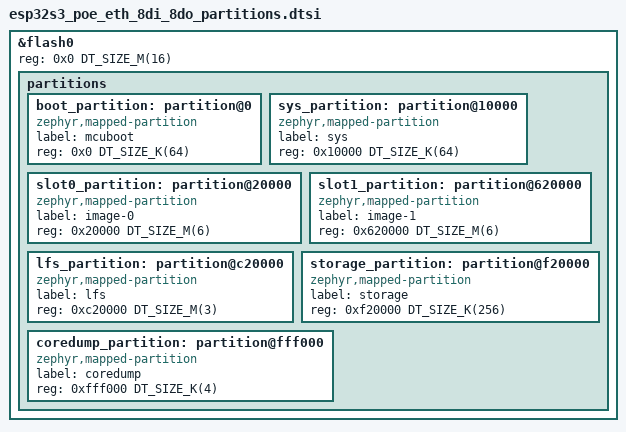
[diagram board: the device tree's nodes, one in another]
/*
 * 16 MB flash layout (ESP32-S3-WROOM-1U-N16R8).
 *
 * Two 6 MB image slots keep room for MCUboot A/B updates (FW-1), a 3 MB
 * LittleFS volume holds the configuration file (CFG-2) and a separate
 * partition backs the settings subsystem (ZMS) for bdSeq (SPB-3).
 *
 * SPDX-License-Identifier: Apache-2.0
 */

&flash0 {
	reg = <0x0 DT_SIZE_M(16)>;
	ranges = <0x0 0x0 DT_SIZE_M(16)>;

	partitions {
		ranges;
		#address-cells = <1>;
		#size-cells = <1>;

		boot_partition: partition@0 {
			compatible = "zephyr,mapped-partition";
			label = "mcuboot";
			reg = <0x0 DT_SIZE_K(64)>;
		};

		sys_partition: partition@10000 {
			compatible = "zephyr,mapped-partition";
			label = "sys";
			reg = <0x10000 DT_SIZE_K(64)>;
		};

		slot0_partition: partition@20000 {
			compatible = "zephyr,mapped-partition";
			label = "image-0";
			reg = <0x20000 DT_SIZE_M(6)>;
		};

		slot1_partition: partition@620000 {
			compatible = "zephyr,mapped-partition";
			label = "image-1";
			reg = <0x620000 DT_SIZE_M(6)>;
		};

		lfs_partition: partition@c20000 {
			compatible = "zephyr,mapped-partition";
			label = "lfs";
			reg = <0xc20000 DT_SIZE_M(3)>;
		};

		storage_partition: partition@f20000 {
			compatible = "zephyr,mapped-partition";
			label = "storage";
			reg = <0xf20000 DT_SIZE_K(256)>;
		};

		coredump_partition: partition@fff000 {
			compatible = "zephyr,mapped-partition";
			label = "coredump";
			reg = <0xfff000 DT_SIZE_K(4)>;
		};
	};
};
